# i2s_secure register map
Vendor: Texas Instruments
Peripheral module from a debugger description file (folder CC35X1E).
Registers are 32-bit, access per field, reset 0x0 unless marked. A register's access mark holds for its fields unless they carry their own. Offsets are as the file gives them; lines under a group give offsets from that group; [hi:lo] are bit positions; {n}, {i} and the like mark numbered series; 'fields as' and 'values as' point back to an identical list; <NAME> marks a mode.

## i2s_secure
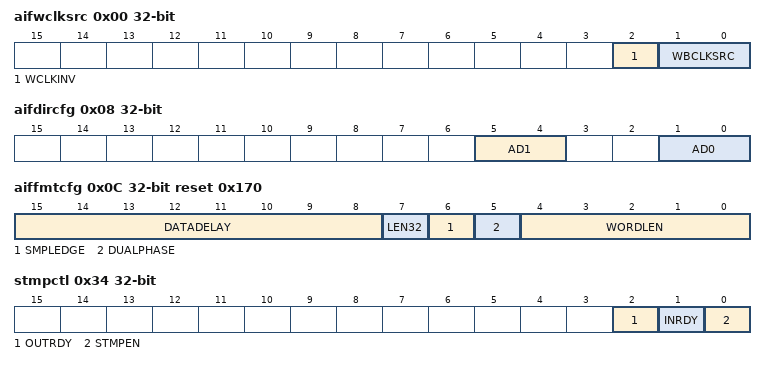
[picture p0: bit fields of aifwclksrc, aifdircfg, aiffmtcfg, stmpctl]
0x00 aifwclksrc — WCLK Source Selection
  [2] WCLKINV rw — Inverts **WCLK** source (pad or internal) when set. 0: Not inverted 1: Inverted
  [1:0] WBCLKSRC rw — Selects **WCLK**/**BCLK** source for **AIF**.
    0=NONE (None ('0')); 1=EXT (External **WCLK** generator, from pad); 2=INT (Internal **WCLK** generator, from module PRCM); 3=RESERVED (Not supported. Will give same **WCLK** as 'NONE' ('00'))
0x04 aifdmacfg — DMA Buffer Size Configuration
  [7:0] ENDFRAMIDX rw — Defines the length of the DMA buffer. Writing a non-zero value to this register field enables and initializes AIF. Note that before doing so, all other configuration must have been done, and [AIFINPTRNEXT.*]/[AIFOUTPTRNEXT.*] must have been loaded.
0x08 aifdircfg — Pin Direction
  [5:4] AD1 rw — Configures the **AD1** audio data pin usage: 0x3: Reserved
    0=DIS (Not in use (disabled)); 1=IN (Input mode); 2=OUT (Output mode)
  [1:0] AD0 rw — Configures the **AD0** audio data pin usage: 0x3: Reserved
    values as AD1
0x0C aiffmtcfg reset 0x170 — Serial Interface Format Configuration
  [15:8] DATADELAY rw — The number of **BCLK** periods between a **WCLK** edge and **MSB** of the first word in a phase: 0x00: **LJF** and **DSP** format 0x01: **I2S** and **DSP** format 0x02: **RJF** format ... 0xFF: **RJF** format Note: When 0, **MSB** of the next word will be output in the idle period between **LSB** of the previous word and the start of the next word. Otherwise logical 0 will be output until the data delay has expired.
  [7] LEN32 rw — The size of each word stored to or loaded from memory:
    0=_16BIT (16-bit (one 16 bit access per sample)); 1=_32BIT (32-bit(one 32-bit access per sample))
  [6] SMPLEDGE rw — On the serial audio interface, data (and wclk) is sampled and clocked out on opposite edges of BCLK.
    0=NEG (Data is sampled on the negative edge and clocked out on the positive edge.); 1=POS (Data is sampled on the positive edge and clocked out on the negative edge.)
  [5] DUALPHASE rw — Selects dual- or single-phase format. 0: Single-phase: **DSP** format 1: Dual-phase: **I2S**, **LJF** and **RJF** formats
  [4:0] WORDLEN rw — Number of bits per word (8-24): In single-phase format, this is the exact number of bits per word. In dual-phase format, this is the maximum number of bits per word. Values below 8 and above 24 give undefined behavior. Data written to memory is always aligned to 16 or 24 bits as defined by [MEM_LEN_24]. Bit widths that differ from this alignment will either be truncated or zero padded.
0x10 aifwmask0 rw reset 0x3 — Word Selection Bit Mask for Pin 0
  [7:0] MASK — Bit-mask indicating valid channels in a frame on AD0. In single-phase mode, each bit represents one channel, starting with **LSB** for the first word in the frame. A frame can contain up to 8 channels. Channels that are not included in the mask will not be sampled and stored in memory, and clocked out as '0'. In dual-phase mode, only the two **LSB**s are considered. For a stereo configuration, set both bits. For a mono configuration, set bit 0 only. In mono mode, only channel 0 will be sampled and stored to memory, and channel 0 will be repeated when clocked out. In mono mode, only channel 0 will be sampled and stored to memory, and channel 0 will be repeated in the second phase when clocked out. If all bits are zero, no input words will be stored to memory, and the output data lines will be constant '0'. This can be utilized when **PWM** debug output is desired without any actively used output pins.
0x14 aifwmask1 reset 0x3 — Word Selection Bit Mask for Pin 1
  [7:0] MASK rw — Bit-mask indicating valid channels in a frame on AD1. In single-phase mode, each bit represents one channel, starting with **LSB** for the first word in the frame. A frame can contain up to 8 channels. Channels that are not included in the mask will not be sampled and stored in memory, and clocked out as '0'. In dual-phase mode, only the two **LSB**s are considered. For a stereo configuration, set both bits. For a mono configuration, set bit 0 only. In mono mode, only channel 0 will be sampled and stored to memory, and channel 0 will be repeated when clocked out. In mono mode, only channel 0 will be sampled and stored to memory, and channel 0 will be repeated in the second phase when clocked out. If all bits are zero, no input words will be stored to memory, and the output data lines will be constant '0'. This can be utilized when **PWM** debug output is desired without any actively used output pins.
0x20 aifinptrnext rw — DMA Input Buffer Next Pointer
  [31:0] PTR — Pointer to the first byte in the next **DMA** input buffer. The read value equals the last written value until the currently used **DMA** input buffer is completed, and then becomes null when the last written value is transferred to the **DMA** controller to start on the next buffer. This event is signalized by [IRQFLAGS-AIF_DMA_IN]. At startup, the value must be written once before and once after configuring the **DMA** buffer size in [AIFDMACFG.*]. The next pointer must be written to this register while the **DMA** function uses the previously written pointer. If not written in time, [IRQFLAGS.PTR_ERR] will be raised and all input pins will be disabled.
0x24 aifinptr ro — DMA Input Buffer Current Pointer
  [31:0] PTR — Value of the **DMA** input buffer pointer currently used by the **DMA** controller. Incremented by 1 (byte) or 2 (word) for each **AHB** access.
0x28 aifoutptrnext rw — DMA Output Buffer Next Pointer
  [31:0] PTR — Pointer to the first byte in the next **DMA** output buffer. The read value equals the last written value until the currently used **DMA** output buffer is completed, and then becomes null when the last written value is transferred to the **DMA** controller to start on the next buffer. This event is signalized by [IRQFLAGS.AIF_DMA_OUT]. At startup, the value must be written once before and once after configuring the **DMA** buffer size in [AIFDMACFG.*]. At this time, the first two samples will be fetched from memory. The next pointer must be written to this register while the **DMA** function uses the previously written pointer. If not written in time, [IRQFLAGS.PTR_ERR] will be raised and all output pins will be disabled.
0x2C aifoutptr ro — DMA Output Buffer Current Pointer
  [31:0] PTR — Value of the **DMA** output buffer pointer currently used by the **DMA** controller Incremented by 1 (byte) or 2 (word) for each **AHB** access.
0x34 stmpctl — Samplestamp Generator Control Register
  [2] OUTRDY ro — Low until the output pins are ready to be started by the samplestamp generator. When started (that is [STMPOUTTRIG.*] equals the **WCLK** counter) the bit goes back low.
  [1] INRDY ro — Low until the input pins are ready to be started by the samplestamp generator. When started (that is [STMPINTRIG.*] equals the **WCLK** counter) the bit goes back low.
  [0] STMPEN rw — Enables the samplestamp generator. The samplestamp generator must only be enabled after it has been properly configured. When cleared, all samplestamp generator counters and capture values are cleared.
0x38 stmpxcntcapt0 ro — Captured **XOSC** Counter Value, Capture Channel 0
  [15:0] CAPTVAL — The value of the samplestamp **XOSC** counter ([STMPXCNT.CURR_VALUE]) last time an event was pulsed (event source selected in [EVENT.I2SSTMPSEL0.EV] for channel 0). This number corresponds to the number of 24 MHz clock cycles since the last positive edge of the selected **WCLK**. The value is cleared when [STMPCTL.STMP_EN] = 0. Note: Due to buffering and synchronization, **WCLK** is delayed by a small number of **BCLK** periods and clk periods. Note: When calculating the fractional part of the sample stamp, [STMPXPER.*] may be less than this bit field.
0x3C stmpxper ro — XOSC Period Value
  [15:0] VALUE — The number of 24 MHz clock cycles in the previous **WCLK** period (that is - the next value of the **XOSC** counter at the positive **WCLK** edge, had it not been reset to 0). The value is cleared when [STMPCTL.STMP_EN] = 0.
0x40 stmpwcntcapt0 ro — Captured **WCLK** Counter Value, Capture Channel 0
  [15:0] CAPTVAL — The value of the samplestamp **WCLK** counter ([STMPWCNT.CURR_VALUE]) last time an event was pulsed (event source selected in [EVENT:I2SSTMPSEL0.EV] for channel 0). This number corresponds to the number of positive **WCLK** edges since the samplestamp generator was enabled (not taking modification through [STMPWADD.*]/[STMPWSET.*] into account). The value is cleared when [STMPCTL.STMP_EN] = 0.
0x44 stmpwper — **WCLK** Counter Period Value
  [15:0] VALUE rw — Used to define when [STMPWCNT.*] is to be reset so number of **WCLK** edges are found for the size of the sample buffer. This is thus a modulo value for the **WCLK** counter. This number must correspond to the size of the sample buffer used by the system (that is the index of the last sample plus 1).
0x48 stmpintrig — WCLK Counter Trigger Value for Input Pins
  [15:0] INSTRTWCNT rw — Compare value used to start the incoming audio streams. This bit field shall equal the **WCLK** counter value during the **WCLK** period in which the first input word(s) are sampled and stored to memory (that is the sample at the start of the very first **DMA** input buffer). The value of this register takes effect when the following conditions are met: - One or more pins are configured as inputs in [AIFDIRCFG.*]. - [AIFDMACFG.*] has been configured for the correct buffer size, and at least 32 **BCLK** cycle ticks have happened. Note: To avoid false triggers, this bit field should be set higher than [STMPWPER.VALUE].
0x4C stmpouttrig — WCLK Counter Trigger Value for Output Pins
  [15:0] OSTRTWCNT rw — OUT START WCNT: Compare value used to start the outgoing audio streams. This bit field must equal the **WCLK** counter value during the **WCLK** period in which the first output word(s) read from memory are clocked out (that is the sample at the start of the very first **DMA** output buffer). The value of this register takes effect when the following conditions are met: - One or more pins are configured as outputs in [AIFDIRCFG.*]. - [AIFDMACFG.*] has been configured for the correct buffer size, and 32 **BCLK** cycle ticks have happened. - 2 samples have been preloaded from memory (examine the [AIFOUTPTR.*] register if necessary). Note: The memory read access is only performed when required, that is channels 0/1 must be selected in [AIFWMASK0.*]/[AIFWMASK1.*]. Note: To avoid false triggers, this bit field should be set higher than [STMPWPER.VALUE].
0x50 stmpwset — WCLK Counter Set Operation
  [15:0] VALUE wo — **WCLK** counter modification: Sets the running **WCLK** counter equal to the written value.
0x54 stmpwadd — WCLK Counter Add Operation
  [15:0] VALINC wo — **WCLK** counter modification: Adds the written value to the running **WCLK** counter. If a positive edge of **WCLK** occurs at the same time as the operation, this will be taken into account. To add a negative value, write "[STMPWPER.VALUE] - value".
0x58 stmpxpermin reset 0xFFFF — XOSC Minimum Period Value Minimum Value of [STMPXPER.*]
  [15:0] VALUE rw — Each time [STMPXPER.*] is updated, the value is also loaded into this register, provided that the value is smaller than the current value in this register. When written, the register is reset to 0xFFFF (65535), regardless of the value written. The minimum value can be used to detect extra **WCLK** pulses (this registers value will be significantly smaller than [STMPXPER.VALUE]).
0x5C stmpwcnt ro — Current Value of WCNT
  [15:0] CURRVAL — Current value of the **WCLK** counter
0x60 stmpxcnt ro — Current Value of XCNT
  [15:0] CURRVAL — Current value of the **XOSC** counter, latched when reading [STMPWCNT.*].
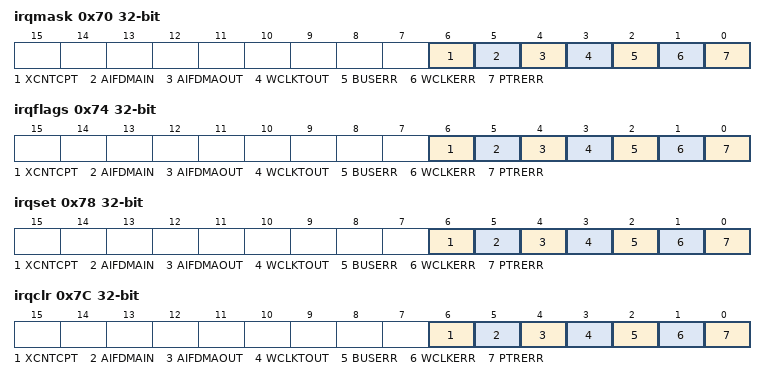
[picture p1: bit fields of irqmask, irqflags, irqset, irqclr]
0x70 irqmask — Interrupt Mask Register Selects mask states of the flags in [IRQFLAGS.*] that contribute to the **I2S_IRQ** event.
  [6] XCNTCPT rw — [IRQFLAGS.XCNT_CAPTURE] interrupt mask 0: Disable 1: Enable
  [5] AIFDMAIN rw — [IRQFLAGS.AIF_DMA_IN] interrupt mask 0: Disable 1: Enable
  [4] AIFDMAOUT rw — [IRQFLAGS.AIF_DMA_OUT] interrupt mask 0: Disable 1: Enable
  [3] WCLKTOUT rw — [IRQFLAGS.WCLK_TIMEOUT] interrupt mask 0: Disable 1: Enable
  [2] BUSERR rw — [IRQFLAGS.BUS_ERR] interrupt mask 0: Disable 1: Enable
  [1] WCLKERR rw — [IRQFLAGS.WCLK_ERR] interrupt mask 0: Disable 1: Enable
  [0] PTRERR rw — [IRQFLAGS.PTR_ERR] interrupt mask. 0: Disable 1: Enable
0x74 irqflags ro — Raw Interrupt Status Register
  [6] XCNTCPT — Will be set when xcnt counter is captured either by events or software. Needs to be cleared by software.
  [5] AIFDMAIN — Set when condition for this bit field event occurs (auto cleared when input pointer is updated - [AIFINPTRNEXT.*]), see description of [AIFINPTRNEXT.*] register for details.
  [4] AIFDMAOUT — Set when condition for this bit field event occurs (auto cleared when output pointer is updated - [AIFOUTPTRNEXT.*]), see description of [AIFOUTPTRNEXT.*] register for details
  [3] WCLKTOUT — Set when the sample stamp generator does not detect a positive **WCLK** edge for 65535 clk periods. This signalizes that the internal or external **BCLK** and **WCLK** generator source has been disabled. The bit is sticky and may only be cleared by software (by writing '1' to [IRQCLR.WCLK_TIMEOUT]).
  [2] BUSERR — Set when a **DMA** operation is not completed in time (that is audio output buffer underflow, or audio input buffer overflow). This error requires a complete restart since word synchronization has been lost. The bit is sticky and may only be cleared by software (by writing '1' to [IRQCLR.BUS_ERR]). Note that DMA initiated transactions to illegal addresses will not trigger an interrupt. The response to such transactions is undefined. INTERNAL_NOTE: The I2S module is not monitoring the AHB bus error response, hence bus faults resulting from access to illegal addresses are not generated. It is best practice to detect and report such errors and, therefore, a ticket has been entered into the CDDS bug tracking database for the I2S module. The reference is CC26_I2S--BUG00011. All versions of CC13xx/CC26xx Chameleon and Lizard are impacted, and there is no plans to change this behavior.
  [1] WCLKERR — Set when: - An unexpected **WCLK** edge occurs during the data delay period of a phase. Note unexpected **WCLK** edges during the word and idle periods of the phase are not detected. - In dual-phase mode, when two **WCLK** edges are less than 4 **BCLK** cycles apart. - In single-phase mode, when a **WCLK** pulse occurs before the last channel. This error requires a complete restart since word synchronization has been lost. The bit is sticky and may only be cleared by software (by writing '1' to [IRQCLR.WCLK_ERR]).
  [0] PTRERR — Set when [AIFINPTRNEXT.*] or [AIFOUTPTRNEXT.*] has not been loaded with the next block address in time. This error requires a complete restart since word synchronization has been lost. The bit is sticky and may only be cleared by software (by writing '1' to [IRQCLR.PTR_ERR]).
0x78 irqset wo — Interrupt Set Register
  [6] XCNTCPT — 1: Sets the interrupt of [IRQFLAGS.XCNT_CAPTURE] (unless a auto clear criteria was given at the same time, in which the set will be ignored)
  [5] AIFDMAIN — 1: Sets the interrupt of [IRQFLAGS.AIF_DMA_IN] (unless a auto clear criteria was given at the same time, in which the set will be ignored)
  [4] AIFDMAOUT — 1: Sets the interrupt of [IRQFLAGS.AIF_DMA_OUT] (unless a auto clear criteria was given at the same time, in which the set will be ignored)
  [3] WCLKTOUT — 1: Sets the interrupt of [IRQFLAGS.WCLK_TIMEOUT]
  [2] BUSERR — 1: Sets the interrupt of [IRQFLAGS.BUS_ERR]
  [1] WCLKERR — 1: Sets the interrupt of [IRQFLAGS.WCLK_ERR]
  [0] PTRERR — 1: Sets the interrupt of [IRQFLAGS.PTR_ERR]
0x7C irqclr wo — Interrupt Clear Register
  [6] XCNTCPT — 1: Clears the interrupt of [IRQFLAGS.XCNT_CAPTURE] (unless a set criteria was given at the same time in which the clear will be ignored)
  [5] AIFDMAIN — 1: Clears the interrupt of [IRQFLAGS.AIF_DMA_IN] (unless a set criteria was given at the same time in which the clear will be ignored)
  [4] AIFDMAOUT — 1: Clears the interrupt of [IRQFLAGS.AIF_DMA_OUT] (unless a set criteria was given at the same time in which the clear will be ignored)
  [3] WCLKTOUT — 1: Clears the interrupt of [IRQFLAGS.WCLK_TIMEOUT] (unless a set criteria was given at the same time in which the clear will be ignored)
  [2] BUSERR — 1: Clears the interrupt of [IRQFLAGS.BUS_ERR] (unless a set criteria was given at the same time in which the clear will be ignored)
  [1] WCLKERR — 1: Clears the interrupt of [IRQFLAGS.WCLK_ERR] (unless a set criteria was given at the same time in which the clear will be ignored)
  [0] PTRERR — 1: Clears the interrupt of [IRQFLAGS.PTR_ERR] (unless a set criteria was given at the same time in which the clear will be ignored)
0x80 aifmclkdiv — **MCLK** Division Ratio
  [9:0] MDIV rw — An unsigned factor of the division ratio used to generate **MCLK** [2-1024]: **MCLK** = MCUCLK/MDIV[Hz] **MCUCLK** is upto 96MHz. A value of 0 is interpreted as 1024. A value of 1 is invalid. If MDIV is odd the low phase of the clock is one **MCUCLK** period longer than the high phase.
0x84 aifbclkdiv — **BCLK** Division Ratio
  [9:0] BDIV rw — An unsigned factor of the division ratio used to generate **BCLK** [2-1024]: **BCLK** = MCUCLK/BDIV[Hz] **MCUCLK** can be upto 96MHz. A value of 0 is interpreted as 1024. A value of 1 is invalid. If BDIV is odd and [AIFCLKCTL.SMPL_ON_POSEDGE.*] = 0, the low phase of the clock is one **MCUCLK** period longer than the high phase. If BDIV is odd and [AIFCLKCTL.SMPL_ON_POSEDGE.*] = 1 , the high phase of the clock is one **MCUCLK** period longer than the low phase.
0x88 aifwclkdiv — **WCLK** Division Ratio
  [15:0] WDIV rw — If [AIFCLKCTL.WCLK_PHASE.*] = 0, Single phase. **WCLK** is high one **BCLK** period and low WDIV[9:0] (unsigned, [1-1023]) **BCLK** periods. **WCLK** = **MCUCLK** / BDIV*(WDIV[9:0] + 1) [Hz] **MCUCLK** upto 96MHz. If [AIFCLKCTL.WCLK_PHASE.*] = 1, Dual phase. Each phase on **WCLK** (50% duty cycle) is WDIV[9:0] (unsigned, [1-1023]) **BCLK** periods. **WCLK **= **MCUCLK **/ BDIV*(2*WDIV[9:0]) [Hz] If [AIFCLKCTL.WCLK_PHASE.*] = 2, User defined. **WCLK** is high WDIV[7:0] (unsigned, [1-255]) **BCLK** periods and low WDIV[15:8] (unsigned, [1-255]) **BCLK** periods. **WCLK** = **MCUCLK **/ (BDIV*(WDIV[7:0] + WDIV[15:8]) [Hz]
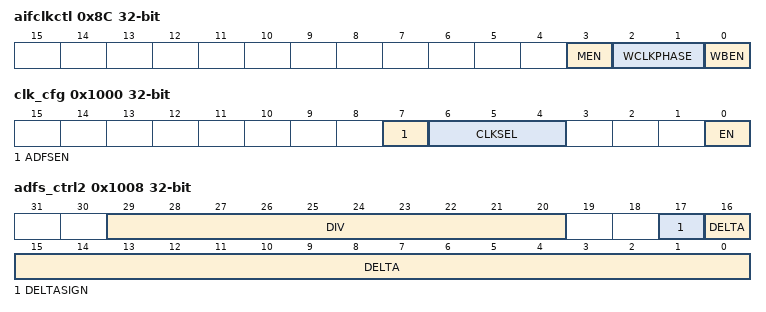
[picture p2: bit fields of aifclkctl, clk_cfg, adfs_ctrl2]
0x8C aifclkctl — Internal Audio Clock Control
  [3] MEN rw — 0: **MCLK** geneartion disabled, 1: **MCLK** generation enabled
  [2:1] WCLKPHASE rw — Decides how the WCLK division ratio is calculated and used to generate different duty cycles (See [AIFWCLKDIV.WDIV.*]).
  [0] WBEN rw — 0: WCLK/BCLK geneartion disabled, 1: WCLK/BCLK generation enabled
0x1000 clk_cfg — Audio clock source selection and **I2S** enable register Note: Disable the [CLKCFG.MEM_CLK_EN] and [CLKCFG.ADFS_EN] to change [CLK_CFG.MEM_CLK_SEL] After changing [CLK_CFG.MEM_CLK_SEL], enable [CLKCFG.ADFS_EN] followed by [CLKCFG.MEM_CLK_EN]
  [7] ADFSEN rw — ADFS enable field
  [6:4] CLKSEL rw — Audio clock selection
    0=SEL_0 (No Clock); 1=SEL_1 (SOC Clock(80MHz)); 2=SEL_2 (SOC PLL Clock(un-swallowed 80MHz)); 3=SEL_3 (HFXT)
  [0] EN rw — 0: **I2S** clock disabled 1: **I2S** clock enabled
0x1004 adfs_ctrl1 — ADFS TREF control register
  [20:0] TREF rw — TREF value for ADFS
0x1008 adfs_ctrl2 — ADFS general configuration register
  [29:20] DIV rw — ADFS div value field
  [17] DELTASIGN rw — ADFS delta sign field
  [16:0] DELTA rw — ADFS delta value field
